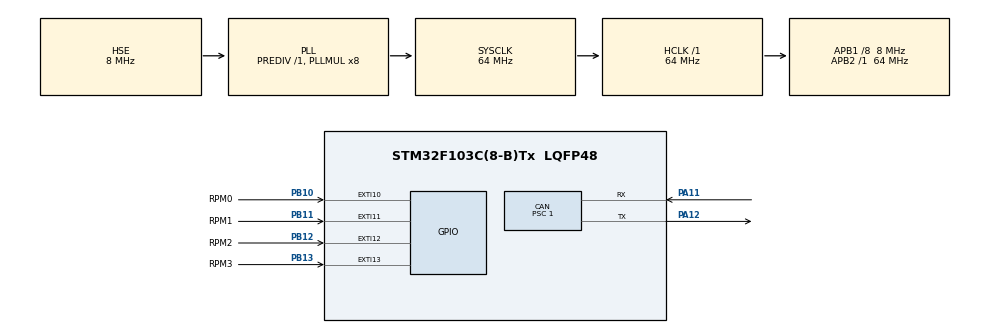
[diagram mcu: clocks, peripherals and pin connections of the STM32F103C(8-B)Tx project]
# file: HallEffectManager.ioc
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CAN.BS1=CAN_BS1_13TQ
CAN.BS2=CAN_BS2_2TQ
CAN.CalculateBaudRate=500000
CAN.CalculateTimeBit=2000
CAN.CalculateTimeQuantum=125.0
CAN.Prescaler=1
CAN.SJW=CAN_SJW_1TQ
Mcu.Family=STM32F1
Mcu.Name=STM32F103C(8-B)Tx
Mcu.Package=LQFP48
NVIC.EXTI15_10_IRQn=true\:0\:0\:false\:false\:true\:true\:true\:true
NVIC.PriorityGroup=NVIC_PRIORITYGROUP_4
NVIC.TIM3_IRQn=true\:0\:0\:false\:false\:true\:true\:true\:true
NVIC.USB_LP_CAN1_RX0_IRQn=true\:0\:0\:false\:false\:true\:true\:true\:true
PA11.Mode=CAN_Activate
PA11.Signal=CAN_RX
PA12.Mode=CAN_Activate
PA12.Signal=CAN_TX
PA13.Mode=Serial_Wire
PA13.Signal=SYS_JTMS-SWDIO
PA14.Mode=Serial_Wire
PA14.Signal=SYS_JTCK-SWCLK
PB10.GPIO_Label=RPM0
PB10.GPIO_ModeDefaultEXTI=GPIO_MODE_IT_FALLING
PB10.Signal=GPXTI10
PB11.GPIO_Label=RPM1
PB11.GPIO_ModeDefaultEXTI=GPIO_MODE_IT_FALLING
PB11.Signal=GPXTI11
PB12.GPIO_Label=RPM2
PB12.GPIO_ModeDefaultEXTI=GPIO_MODE_IT_FALLING
PB12.Signal=GPXTI12
PB13.GPIO_Label=RPM3
PB13.GPIO_ModeDefaultEXTI=GPIO_MODE_IT_FALLING
PB13.Signal=GPXTI13
PC14-OSC32_IN.Mode=LSE-External-Oscillator
PC14-OSC32_IN.Signal=RCC_OSC32_IN
PC15-OSC32_OUT.Mode=LSE-External-Oscillator
PC15-OSC32_OUT.Signal=RCC_OSC32_OUT
PD0-OSC_IN.Mode=HSE-External-Oscillator
PD0-OSC_IN.Signal=RCC_OSC_IN
PD1-OSC_OUT.Mode=HSE-External-Oscillator
PD1-OSC_OUT.Signal=RCC_OSC_OUT
ProjectManager.HeapSize=0x200
ProjectManager.StackSize=0x400
ProjectManager.TargetToolchain=Makefile
RCC.AHBFreq_Value=64000000
RCC.APB1CLKDivider=RCC_HCLK_DIV8
RCC.APB1Freq_Value=8000000
RCC.APB1TimFreq_Value=16000000
RCC.APB2Freq_Value=64000000
RCC.APB2TimFreq_Value=64000000
RCC.HCLKFreq_Value=64000000
RCC.PLLMUL=RCC_PLL_MUL8
RCC.PLLSourceVirtual=RCC_PLLSOURCE_HSE
RCC.PREFETCH_ENABLE=0
RCC.SYSCLKFreq_VALUE=64000000
RCC.SYSCLKSource=RCC_SYSCLKSOURCE_PLLCLK
RCC.USBFreq_Value=64000000
RCC.VDD_VALUE=3.3
TIM1.Period=9999
TIM1.Prescaler=639
TIM1.TIM_MasterOutputTrigger=TIM_TRGO_UPDATE
TIM3.Period=99
TIM3.Prescaler=1599
VP_TIM1_VS_ClockSourceINT.Mode=Internal
VP_TIM2_VS_ClockSourceITR.Mode=TriggerSource_ITR0
VP_TIM2_VS_ControllerModeClock.Mode=Clock Mode
VP_TIM3_VS_ClockSourceINT.Mode=Internal
board=custom

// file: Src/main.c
/* USER CODE BEGIN Header */
/**
  ******************************************************************************
  * @file           : main.c
  * @brief          : Main program body
  ******************************************************************************
  * @attention
  *
  * Copyright (c) 2025 STMicroelectronics.
  * All rights reserved.
  *
  * This software is licensed under terms that can be found in the LICENSE file
  * in the root directory of this software component.
  * If no LICENSE file comes with this software, it is provided AS-IS.
  *
  ******************************************************************************
  */
/* USER CODE END Header */
#include "main.h"
#include "can.h"
#include "tim.h"
#include "gpio.h"

/* USER CODE BEGIN Includes */
#include "Cu_main.h"
/* USER CODE END Includes */

void SystemClock_Config(void);

int main(void)
{

  /* MCU Configuration--------------------------------------------------------*/

  /* Reset of all peripherals, Initializes the Flash interface and the Systick. */
  HAL_Init();

  /* Configure the system clock */
  SystemClock_Config();

  /* Initialize all configured peripherals */
  MX_GPIO_Init();
  MX_CAN_Init();
  MX_TIM1_Init();
  MX_TIM2_Init();
  MX_TIM3_Init();
  /* USER CODE BEGIN 2 */
  Cu_main();
  /* USER CODE END 2 */

  /* Infinite loop */
  while (1)
  {

  }
}

void SystemClock_Config(void)
{
  RCC_OscInitTypeDef RCC_OscInitStruct = {0};
  RCC_ClkInitTypeDef RCC_ClkInitStruct = {0};

  /** Initializes the RCC Oscillators according to the specified parameters
  * in the RCC_OscInitTypeDef structure.
  */
  RCC_OscInitStruct.OscillatorType = RCC_OSCILLATORTYPE_HSE;
  RCC_OscInitStruct.HSEState = RCC_HSE_ON;
  RCC_OscInitStruct.HSEPredivValue = RCC_HSE_PREDIV_DIV1;
  RCC_OscInitStruct.HSIState = RCC_HSI_ON;
  RCC_OscInitStruct.PLL.PLLState = RCC_PLL_ON;
  RCC_OscInitStruct.PLL.PLLSource = RCC_PLLSOURCE_HSE;
  RCC_OscInitStruct.PLL.PLLMUL = RCC_PLL_MUL8;
  if (HAL_RCC_OscConfig(&RCC_OscInitStruct) != HAL_OK)
  {
    Error_Handler();
  }

  /** Initializes the CPU, AHB and APB buses clocks
  */
  RCC_ClkInitStruct.ClockType = RCC_CLOCKTYPE_HCLK|RCC_CLOCKTYPE_SYSCLK
                              |RCC_CLOCKTYPE_PCLK1|RCC_CLOCKTYPE_PCLK2;
  RCC_ClkInitStruct.SYSCLKSource = RCC_SYSCLKSOURCE_PLLCLK;
  RCC_ClkInitStruct.AHBCLKDivider = RCC_SYSCLK_DIV1;
  RCC_ClkInitStruct.APB1CLKDivider = RCC_HCLK_DIV8;
  RCC_ClkInitStruct.APB2CLKDivider = RCC_HCLK_DIV1;

  if (HAL_RCC_ClockConfig(&RCC_ClkInitStruct, FLASH_LATENCY_2) != HAL_OK)
  {
    Error_Handler();
  }
}

void Error_Handler(void)
{
  __disable_irq();
  while (1)
  {
  }
}
